VERSION "Body_CAN_v1.0"

NS_ :

BS_:

BU_: BCM ADAS CGW DATC SMK BODY_SECURITY_MODULE WIPER_MODULE AFLS DOOR_FL DOOR_FR SEAT_DRV SEAT_PASS VAL_SCENARIO_CTRL

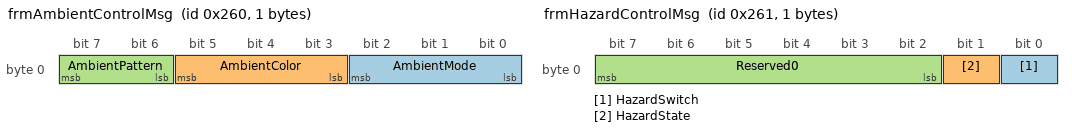
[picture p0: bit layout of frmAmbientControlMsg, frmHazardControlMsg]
BO_ 608 frmAmbientControlMsg: 1 BCM
 SG_ AmbientMode : 0|3@1+ (1,0) [0|7] ""  BCM
 SG_ AmbientColor : 3|3@1+ (1,0) [0|7] ""  BCM
 SG_ AmbientPattern : 6|2@1+ (1,0) [0|3] ""  BCM

BO_ 609 frmHazardControlMsg: 1 BCM
 SG_ HazardSwitch : 0|1@1+ (1,0) [0|1] ""  BCM
 SG_ HazardState : 1|1@1+ (1,0) [0|1] ""  BCM
 SG_ Reserved0 : 2|6@1+ (1,0) [0|0] "" Vector__XXX

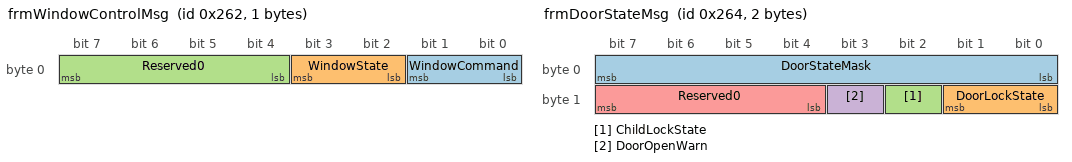
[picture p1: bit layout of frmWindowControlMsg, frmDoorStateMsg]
BO_ 610 frmWindowControlMsg: 1 BCM
 SG_ WindowCommand : 0|2@1+ (1,0) [0|3] ""  BCM
 SG_ WindowState : 2|2@1+ (1,0) [0|3] ""  BCM
 SG_ Reserved0 : 4|4@1+ (1,0) [0|0] "" Vector__XXX

BO_ 612 frmDoorStateMsg: 2 BCM
 SG_ DoorStateMask : 0|8@1+ (1,0) [0|255] ""  BCM
 SG_ DoorLockState : 8|2@1+ (1,0) [0|3] ""  BCM
 SG_ ChildLockState : 10|1@1+ (1,0) [0|1] ""  BCM
 SG_ DoorOpenWarn : 11|1@1+ (1,0) [0|1] ""  BCM
 SG_ Reserved0 : 12|4@1+ (1,0) [0|0] "" Vector__XXX

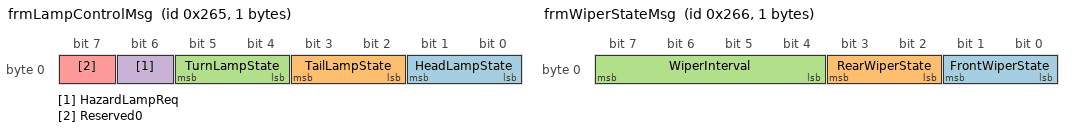
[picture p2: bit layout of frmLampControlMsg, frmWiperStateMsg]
BO_ 613 frmLampControlMsg: 1 BCM
 SG_ HeadLampState : 0|2@1+ (1,0) [0|3] ""  BCM
 SG_ TailLampState : 2|2@1+ (1,0) [0|3] ""  BCM
 SG_ TurnLampState : 4|2@1+ (1,0) [0|3] ""  BCM
 SG_ HazardLampReq : 6|1@1+ (1,0) [0|1] ""  BCM
 SG_ Reserved0 : 7|1@1+ (1,0) [0|0] "" Vector__XXX

BO_ 614 frmWiperStateMsg: 1 WIPER_MODULE
 SG_ FrontWiperState : 0|2@1+ (1,0) [0|3] ""  WIPER_MODULE
 SG_ RearWiperState : 2|2@1+ (1,0) [0|3] ""  WIPER_MODULE
 SG_ WiperInterval : 4|4@1+ (1,0) [0|15] ""  WIPER_MODULE

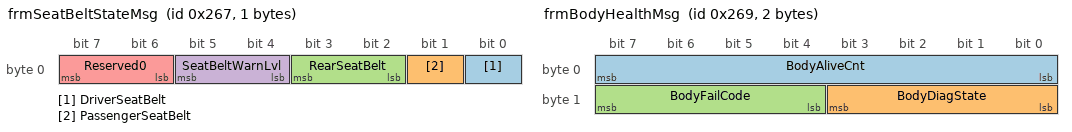
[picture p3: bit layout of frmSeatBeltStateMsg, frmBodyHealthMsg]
BO_ 615 frmSeatBeltStateMsg: 1 BCM
 SG_ DriverSeatBelt : 0|1@1+ (1,0) [0|1] ""  BCM
 SG_ PassengerSeatBelt : 1|1@1+ (1,0) [0|1] ""  BCM
 SG_ RearSeatBelt : 2|2@1+ (1,0) [0|3] ""  BCM
 SG_ SeatBeltWarnLvl : 4|2@1+ (1,0) [0|3] ""  BCM
 SG_ Reserved0 : 6|2@1+ (1,0) [0|0] "" Vector__XXX

BO_ 616 frmCabinAirStateMsg: 2 BCM
 SG_ CabinTemp : 0|8@1+ (1,0) [0|100] "degC"  BCM
 SG_ AirQualityIndex : 8|8@1+ (1,0) [0|255] ""  BCM

BO_ 617 frmBodyHealthMsg: 2 BCM
 SG_ BodyAliveCnt : 0|8@1+ (1,0) [0|255] ""  VAL_SCENARIO_CTRL,CGW
 SG_ BodyDiagState : 8|4@1+ (1,0) [0|15] ""  VAL_SCENARIO_CTRL,CGW
 SG_ BodyFailCode : 12|4@1+ (1,0) [0|15] ""  VAL_SCENARIO_CTRL,CGW

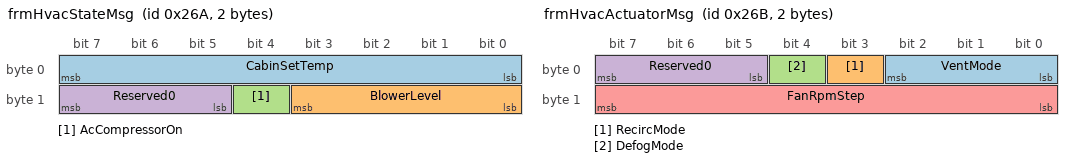
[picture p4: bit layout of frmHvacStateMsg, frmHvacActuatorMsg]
BO_ 618 frmHvacStateMsg: 2 DATC
 SG_ CabinSetTemp : 0|8@1+ (1,0) [0|100] "degC"  BCM
 SG_ BlowerLevel : 8|4@1+ (1,0) [0|15] ""  BCM
 SG_ AcCompressorOn : 12|1@1+ (1,0) [0|1] ""  BCM
 SG_ Reserved0 : 13|3@1+ (1,0) [0|0] "" Vector__XXX

BO_ 619 frmHvacActuatorMsg: 2 DATC
 SG_ VentMode : 0|3@1+ (1,0) [0|7] ""  BCM
 SG_ RecircMode : 3|1@1+ (1,0) [0|1] ""  BCM
 SG_ DefogMode : 4|1@1+ (1,0) [0|1] ""  BCM
 SG_ Reserved0 : 5|3@1+ (1,0) [0|0] "" Vector__XXX
 SG_ FanRpmStep : 8|8@1+ (1,0) [0|255] ""  BCM

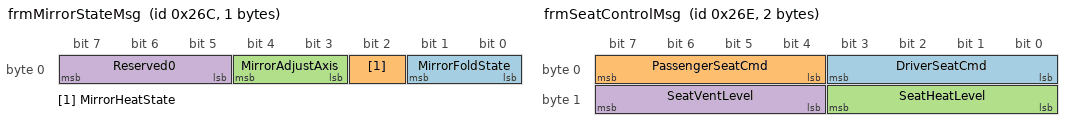
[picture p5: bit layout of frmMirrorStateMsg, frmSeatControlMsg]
BO_ 620 frmMirrorStateMsg: 1 BCM
 SG_ MirrorFoldState : 0|2@1+ (1,0) [0|3] ""  BCM
 SG_ MirrorHeatState : 2|1@1+ (1,0) [0|1] ""  BCM
 SG_ MirrorAdjustAxis : 3|2@1+ (1,0) [0|3] ""  BCM
 SG_ Reserved0 : 5|3@1+ (1,0) [0|0] "" Vector__XXX

BO_ 621 frmSeatStateMsg: 2 BCM
 SG_ DriverSeatPos : 0|8@1+ (1,0) [0|255] ""  BCM
 SG_ PassengerSeatPos : 8|8@1+ (1,0) [0|255] ""  BCM

BO_ 622 frmSeatControlMsg: 2 BCM
 SG_ DriverSeatCmd : 0|4@1+ (1,0) [0|15] ""  BCM
 SG_ PassengerSeatCmd : 4|4@1+ (1,0) [0|15] ""  BCM
 SG_ SeatHeatLevel : 8|4@1+ (1,0) [0|15] ""  BCM
 SG_ SeatVentLevel : 12|4@1+ (1,0) [0|15] ""  BCM

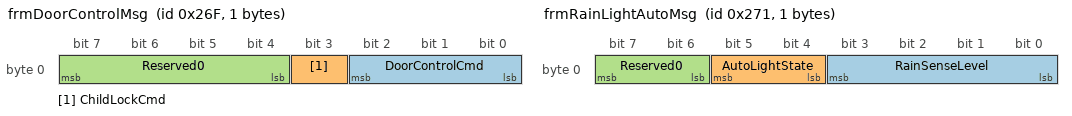
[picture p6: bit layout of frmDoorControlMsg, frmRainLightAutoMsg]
BO_ 623 frmDoorControlMsg: 1 BCM
 SG_ DoorControlCmd : 0|3@1+ (1,0) [0|7] ""  BCM
 SG_ ChildLockCmd : 3|1@1+ (1,0) [0|1] ""  BCM
 SG_ Reserved0 : 4|4@1+ (1,0) [0|0] "" Vector__XXX

BO_ 624 frmInteriorLightMsg: 1 BCM
 SG_ CabinLightMode : 0|3@1+ (1,0) [0|7] ""  BCM
 SG_ DomeLightLevel : 3|5@1+ (1,0) [0|31] ""  BCM

BO_ 625 frmRainLightAutoMsg: 1 BCM
 SG_ RainSenseLevel : 0|4@1+ (1,0) [0|15] ""  BCM
 SG_ AutoLightState : 4|2@1+ (1,0) [0|3] ""  BCM
 SG_ Reserved0 : 6|2@1+ (1,0) [0|0] "" Vector__XXX

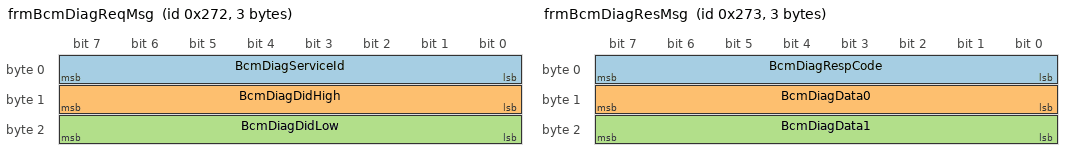
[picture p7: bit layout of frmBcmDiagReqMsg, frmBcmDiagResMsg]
BO_ 626 frmBcmDiagReqMsg: 3 BCM
 SG_ BcmDiagServiceId : 0|8@1+ (1,0) [0|255] ""  BCM
 SG_ BcmDiagDidHigh : 8|8@1+ (1,0) [0|255] ""  BCM
 SG_ BcmDiagDidLow : 16|8@1+ (1,0) [0|255] ""  BCM

BO_ 627 frmBcmDiagResMsg: 3 BCM
 SG_ BcmDiagRespCode : 0|8@1+ (1,0) [0|255] ""  BCM
 SG_ BcmDiagData0 : 8|8@1+ (1,0) [0|255] ""  BCM
 SG_ BcmDiagData1 : 16|8@1+ (1,0) [0|255] ""  BCM

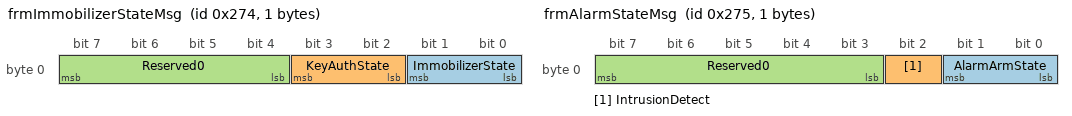
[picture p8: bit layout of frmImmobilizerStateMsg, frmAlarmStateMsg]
BO_ 628 frmImmobilizerStateMsg: 1 SMK
 SG_ ImmobilizerState : 0|2@1+ (1,0) [0|3] ""  SMK
 SG_ KeyAuthState : 2|2@1+ (1,0) [0|3] ""  SMK
 SG_ Reserved0 : 4|4@1+ (1,0) [0|0] "" Vector__XXX

BO_ 629 frmAlarmStateMsg: 1 BODY_SECURITY_MODULE
 SG_ AlarmArmState : 0|2@1+ (1,0) [0|3] ""  BODY_SECURITY_MODULE
 SG_ IntrusionDetect : 2|1@1+ (1,0) [0|1] ""  BODY_SECURITY_MODULE
 SG_ Reserved0 : 3|5@1+ (1,0) [0|0] "" Vector__XXX

BO_ 630 frmBodyGatewayStateMsg: 2 BCM
 SG_ BodyGwRouteState : 0|8@1+ (1,0) [0|255] ""  ADAS
 SG_ BodyGwHealth : 8|8@1+ (1,0) [0|255] ""  ADAS

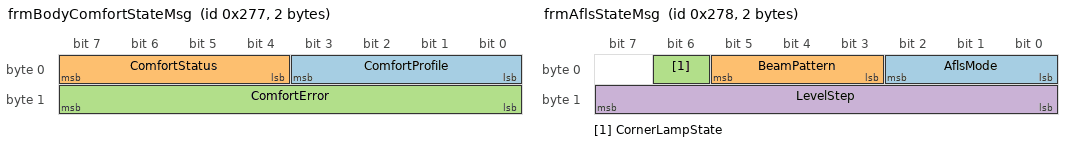
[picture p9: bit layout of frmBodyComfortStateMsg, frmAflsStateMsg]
BO_ 631 frmBodyComfortStateMsg: 2 BCM
 SG_ ComfortProfile : 0|4@1+ (1,0) [0|15] ""  ADAS
 SG_ ComfortStatus : 4|4@1+ (1,0) [0|15] ""  ADAS
 SG_ ComfortError : 8|8@1+ (1,0) [0|255] ""  ADAS

BO_ 632 frmAflsStateMsg: 2 AFLS
 SG_ AflsMode : 0|3@1+ (1,0) [0|7] ""  AFLS
 SG_ BeamPattern : 3|3@1+ (1,0) [0|7] ""  AFLS
 SG_ CornerLampState : 6|1@1+ (1,0) [0|1] ""  AFLS
 SG_ LevelStep : 8|8@1+ (1,0) [0|255] ""  AFLS

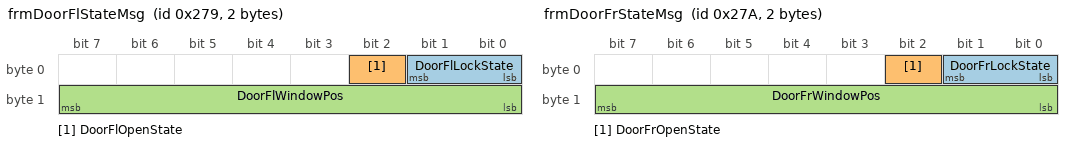
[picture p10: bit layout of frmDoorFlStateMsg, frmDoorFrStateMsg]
BO_ 633 frmDoorFlStateMsg: 2 DOOR_FL
 SG_ DoorFlLockState : 0|2@1+ (1,0) [0|3] ""  DOOR_FL
 SG_ DoorFlOpenState : 2|1@1+ (1,0) [0|1] ""  DOOR_FL
 SG_ DoorFlWindowPos : 8|8@1+ (1,0) [0|255] "%"  DOOR_FL

BO_ 634 frmDoorFrStateMsg: 2 DOOR_FR
 SG_ DoorFrLockState : 0|2@1+ (1,0) [0|3] ""  DOOR_FR
 SG_ DoorFrOpenState : 2|1@1+ (1,0) [0|1] ""  DOOR_FR
 SG_ DoorFrWindowPos : 8|8@1+ (1,0) [0|255] "%"  DOOR_FR

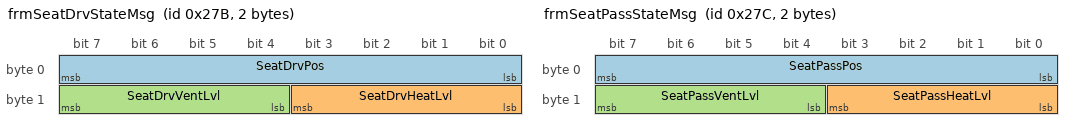
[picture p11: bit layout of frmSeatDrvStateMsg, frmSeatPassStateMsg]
BO_ 635 frmSeatDrvStateMsg: 2 SEAT_DRV
 SG_ SeatDrvPos : 0|8@1+ (1,0) [0|255] ""  SEAT_DRV
 SG_ SeatDrvHeatLvl : 8|4@1+ (1,0) [0|15] ""  SEAT_DRV
 SG_ SeatDrvVentLvl : 12|4@1+ (1,0) [0|15] ""  SEAT_DRV

BO_ 636 frmSeatPassStateMsg: 2 SEAT_PASS
 SG_ SeatPassPos : 0|8@1+ (1,0) [0|255] ""  SEAT_PASS
 SG_ SeatPassHeatLvl : 8|4@1+ (1,0) [0|15] ""  SEAT_PASS
 SG_ SeatPassVentLvl : 12|4@1+ (1,0) [0|15] ""  SEAT_PASS

CM_ BO_ 608 "Flow_007 ambient output.";
CM_ BO_ 609 "Body baseline: hazard switch and hazard state.";
CM_ BO_ 610 "Body baseline: window command and window state.";
CM_ BO_ 612 "Body baseline: door mask/lock/child-lock/open-warning state.";
CM_ BO_ 613 "Body baseline: lamp and hazard request state.";
CM_ BO_ 614 "Body baseline: front/rear wiper state and interval.";
CM_ BO_ 615 "Body baseline: seat-belt occupancy and warning level.";
CM_ BO_ 616 "Body baseline: cabin temperature and air quality index.";
CM_ BO_ 617 "Body health/diagnostic state.";
CM_ BO_ 618 "Comm_202: HVAC state extension.";
CM_ BO_ 619 "Comm_202: HVAC actuator extension.";
CM_ BO_ 620 "Comm_202: mirror state extension.";
CM_ BO_ 621 "Comm_202: seat state extension.";
CM_ BO_ 622 "Comm_202: seat control extension.";
CM_ BO_ 623 "Comm_202: door control extension.";
CM_ BO_ 624 "Comm_202: interior light extension.";
CM_ BO_ 625 "Comm_202: rain/light auto extension.";
CM_ BO_ 626 "Comm_202: BCM diagnostic request.";
CM_ BO_ 627 "Comm_202: BCM diagnostic response.";
CM_ BO_ 628 "Comm_202: immobilizer state extension.";
CM_ BO_ 629 "Comm_202: alarm state extension.";
CM_ BO_ 630 "Comm_202: body gateway status extension.";
CM_ BO_ 631 "Comm_202: body comfort status extension.";
CM_ BO_ 632 "Comm_202: adaptive front lighting state extension.";
CM_ BO_ 633 "Comm_202: front-left door module state extension.";
CM_ BO_ 634 "Comm_202: front-right door module state extension.";
CM_ BO_ 635 "Comm_202: driver seat module state extension.";
CM_ BO_ 636 "Comm_202: passenger seat module state extension.";
BA_DEF_ BO_  "GenMsgCycleTime" INT 0 10000;
BA_DEF_DEF_  "GenMsgCycleTime" 0;
BA_ "GenMsgCycleTime" BO_ 608 50;
BA_ "GenMsgCycleTime" BO_ 609 100;
BA_ "GenMsgCycleTime" BO_ 610 100;
BA_ "GenMsgCycleTime" BO_ 612 100;
BA_ "GenMsgCycleTime" BO_ 613 100;
BA_ "GenMsgCycleTime" BO_ 614 100;
BA_ "GenMsgCycleTime" BO_ 615 100;
BA_ "GenMsgCycleTime" BO_ 616 100;
BA_ "GenMsgCycleTime" BO_ 617 100;
BA_ "GenMsgCycleTime" BO_ 618 100;
BA_ "GenMsgCycleTime" BO_ 619 100;
BA_ "GenMsgCycleTime" BO_ 620 100;
BA_ "GenMsgCycleTime" BO_ 621 100;
BA_ "GenMsgCycleTime" BO_ 622 100;
BA_ "GenMsgCycleTime" BO_ 623 100;
BA_ "GenMsgCycleTime" BO_ 624 100;
BA_ "GenMsgCycleTime" BO_ 625 100;
BA_ "GenMsgCycleTime" BO_ 628 100;
BA_ "GenMsgCycleTime" BO_ 629 100;
BA_ "GenMsgCycleTime" BO_ 630 100;
BA_ "GenMsgCycleTime" BO_ 631 100;
BA_ "GenMsgCycleTime" BO_ 632 100;
BA_ "GenMsgCycleTime" BO_ 633 100;
BA_ "GenMsgCycleTime" BO_ 634 100;
BA_ "GenMsgCycleTime" BO_ 635 100;
BA_ "GenMsgCycleTime" BO_ 636 100;
VAL_ 608 AmbientMode 0 "Off" 1 "Basic" 2 "Caution" 3 "SchoolZone" 4 "Reserved" 5 "GuideLeft" 6 "GuideRight" 7 "Emergency" ;
VAL_ 608 AmbientColor 0 "White" 1 "Blue" 2 "Green" 3 "Yellow" 4 "Orange" 5 "Red" 6 "Purple" 7 "Rainbow" ;
VAL_ 608 AmbientPattern 0 "Solid" 1 "Breathing" 2 "Pulse" 3 "Wave" ;
VAL_ 609 HazardSwitch 0 "Off" 1 "On" ;
VAL_ 609 HazardState 0 "Inactive" 1 "Active" ;
VAL_ 610 WindowCommand 0 "NoCmd" 1 "Open" 2 "Close" 3 "Stop" ;
VAL_ 610 WindowState 0 "Unknown" 1 "Opened" 2 "Closed" 3 "Moving" ;
VAL_ 612 DoorLockState 0 "Unlocked" 1 "Locked" 2 "AutoLock" 3 "Fault" ;
VAL_ 612 ChildLockState 0 "Off" 1 "On" ;
VAL_ 612 DoorOpenWarn 0 "NoWarn" 1 "Warn" ;
VAL_ 613 HeadLampState 0 "Off" 1 "Parking" 2 "LowBeam" 3 "HighBeam" ;
VAL_ 613 TailLampState 0 "Off" 1 "On" 2 "Auto" 3 "Fault" ;
VAL_ 613 TurnLampState 0 "Off" 1 "Left" 2 "Right" 3 "Hazard" ;
VAL_ 613 HazardLampReq 0 "Off" 1 "On" ;
VAL_ 614 FrontWiperState 0 "Off" 1 "Low" 2 "High" 3 "Auto" ;
VAL_ 614 RearWiperState 0 "Off" 1 "On" 2 "Intermittent" 3 "Fault" ;
VAL_ 615 DriverSeatBelt 0 "Unbuckled" 1 "Buckled" ;
VAL_ 615 PassengerSeatBelt 0 "Unbuckled" 1 "Buckled" ;
VAL_ 615 RearSeatBelt 0 "None" 1 "SomeUnbuckled" 2 "AllBuckled" 3 "Fault" ;
VAL_ 615 SeatBeltWarnLvl 0 "None" 1 "Info" 2 "Warn" 3 "Critical" ;
VAL_ 617 BodyDiagState 0 "Normal" 1 "Init" 2 "Warning" 3 "Degraded" 4 "Fault" 5 "Test" ;
VAL_ 618 AcCompressorOn 1 "active" 0 "Inactive" ;
VAL_ 619 VentMode 0 "Off" 1 "Face" 2 "Foot" 3 "Defrost" 4 "FaceFoot" 5 "FaceDefrost" 6 "FootDefrost" 7 "All" ;
VAL_ 619 RecircMode 1 "Recirc" 0 "Fresh" ;
VAL_ 619 DefogMode 1 "On" 0 "Off" ;
VAL_ 620 MirrorFoldState 0 "Unfolded" 1 "Folded" 2 "Folding" 3 "Unfolding" ;
VAL_ 620 MirrorHeatState 0 "Off" 1 "On" ;
VAL_ 620 MirrorAdjustAxis 0 "None" 1 "Horizontal" 2 "Vertical" 3 "Reserved" ;
VAL_ 622 DriverSeatCmd 0 "NoCmd" 1 "SlideForward" 2 "SlideBackward" 3 "HeightUp" 4 "HeightDown" 5 "ReclineForward" 6 "ReclineBackward" 7 "CushionTiltUp" 8 "CushionTiltDown" 9 "LumbarForward" 10 "LumbarBackward" 11 "MemorySet" 12 "MemoryRecall" 13 "EasyEntry" 14 "Massage" 15 "Stop" ;
VAL_ 622 PassengerSeatCmd 0 "NoCmd" 1 "SlideForward" 2 "SlideBackward" 3 "HeightUp" 4 "HeightDown" 5 "ReclineForward" 6 "ReclineBackward" 7 "CushionTiltUp" 8 "CushionTiltDown" 9 "LumbarForward" 10 "LumbarBackward" 11 "MemorySet" 12 "MemoryRecall" 13 "EasyEntry" 14 "Massage" 15 "Stop" ;
VAL_ 623 DoorControlCmd 0 "NoCmd" 1 "Lock" 2 "Unlock" 3 "Open" 4 "Close" 5 "Stop" 6 "TrunkRelease" 7 "Reserved" ;
VAL_ 623 ChildLockCmd 0 "Disable" 1 "Enable" ;
VAL_ 624 CabinLightMode 0 "Off" 1 "On" 2 "DoorLinked" 3 "Auto" 4 "Reading" 5 "Ambient" 6 "Courtesy" 7 "Fault" ;
VAL_ 625 AutoLightState 0 "Off" 1 "Standby" 2 "Active" 3 "Fault" ;
VAL_ 628 ImmobilizerState 0 "Disarmed" 1 "Armed" 2 "Locked" 3 "Fault" ;
VAL_ 628 KeyAuthState 0 "NoKey" 1 "AuthOk" 2 "AuthFail" 3 "Expired" ;
VAL_ 629 AlarmArmState 0 "Disarmed" 1 "Armed" 2 "Triggered" 3 "Fault" ;
VAL_ 629 IntrusionDetect 0 "NoDetect" 1 "Detected" ;
VAL_ 630 BodyGwRouteState 0 "Normal" 1 "Degraded" 2 "Isolated" 3 "Fault" ;
VAL_ 630 BodyGwHealth 0 "Ok" 1 "Warning" 2 "Degraded" 3 "Fault" ;
VAL_ 631 ComfortProfile 0 "Default" 1 "Relax" 2 "Warm" 3 "Cool" 4 "Driver" 5 "Passenger" 6 "Family" 7 "Valet" 8 "User1" 9 "User2" ;
VAL_ 631 ComfortStatus 0 "Idle" 1 "Applying" 2 "Active" 3 "Completed" 4 "Canceled" 5 "Fault" 6 "Timeout" ;
